VERSION ""

NS_ :

BS_:

BU_: MASTER BMSLV DASH DAQ DRIVE CHARGER TCS IMU DEBUG SPID DRS GPS SOC MOTEC

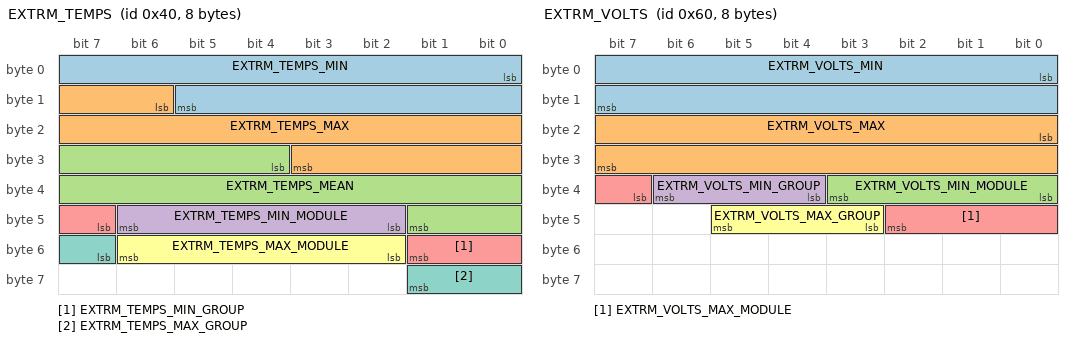
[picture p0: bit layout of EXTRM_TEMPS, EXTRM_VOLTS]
BO_ 64 EXTRM_TEMPS: 8 MASTER
 SG_ EXTRM_TEMPS_MIN : 0|14@1+ (0.0054931640625,0) [0|90] "�C" DEBUG
 SG_ EXTRM_TEMPS_MAX : 14|14@1+ (0.0054931640625,0) [0|90] "�C" DEBUG
 SG_ EXTRM_TEMPS_MEAN : 28|14@1+ (0.0054931640625,0) [0|90] "�C" DEBUG
 SG_ EXTRM_TEMPS_MIN_MODULE : 42|5@1+ (1,1) [1|32] "" DEBUG
 SG_ EXTRM_TEMPS_MIN_GROUP : 47|3@1+ (1,1) [1|6] "" DEBUG
 SG_ EXTRM_TEMPS_MAX_MODULE : 50|5@1+ (1,1) [1|32] "" DEBUG
 SG_ EXTRM_TEMPS_MAX_GROUP : 55|3@1+ (1,1) [1|6] "" DEBUG

BO_ 96 EXTRM_VOLTS: 8 MASTER
 SG_ EXTRM_VOLTS_MIN : 0|16@1+ (0.042724609375,1600) [1600|4400] "mV" DEBUG
 SG_ EXTRM_VOLTS_MAX : 16|16@1+ (0.042724609375,1600) [1600|4400] "mV" DEBUG
 SG_ EXTRM_VOLTS_MIN_MODULE : 32|4@1+ (1,1) [1|16] "" DEBUG
 SG_ EXTRM_VOLTS_MIN_GROUP : 36|3@1+ (1,1) [1|6] "" DEBUG
 SG_ EXTRM_VOLTS_MAX_MODULE : 39|4@1+ (1,1) [1|16] "" DEBUG
 SG_ EXTRM_VOLTS_MAX_GROUP : 43|3@1+ (1,1) [1|6] "" DEBUG

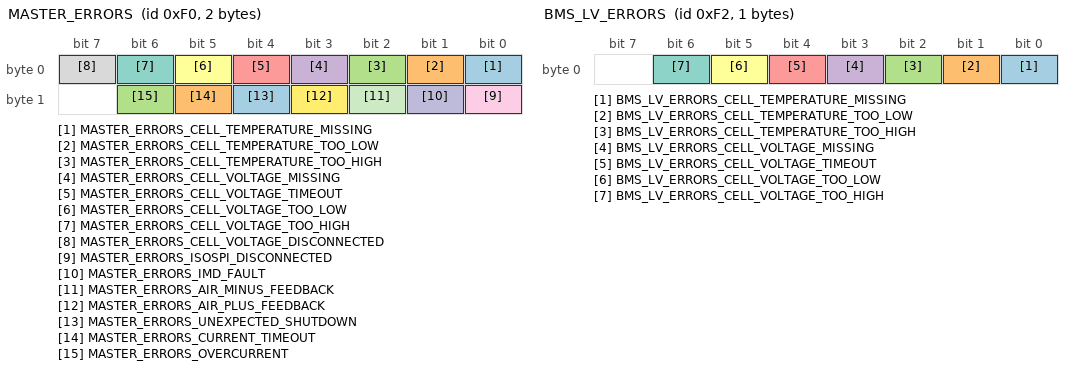
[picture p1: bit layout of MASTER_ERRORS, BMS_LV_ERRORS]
BO_ 240 MASTER_ERRORS: 2 MASTER
 SG_ MASTER_ERRORS_CELL_TEMPERATURE_MISSING : 0|1@1+ (1,0) [0|1] "" DEBUG
 SG_ MASTER_ERRORS_CELL_TEMPERATURE_TOO_LOW : 1|1@1+ (1,0) [0|1] "" DEBUG
 SG_ MASTER_ERRORS_CELL_TEMPERATURE_TOO_HIGH : 2|1@1+ (1,0) [0|1] "" DEBUG
 SG_ MASTER_ERRORS_CELL_VOLTAGE_MISSING : 3|1@1+ (1,0) [0|1] "" DEBUG
 SG_ MASTER_ERRORS_CELL_VOLTAGE_TIMEOUT : 4|1@1+ (1,0) [0|1] "" DEBUG
 SG_ MASTER_ERRORS_CELL_VOLTAGE_TOO_LOW : 5|1@1+ (1,0) [0|1] "" DEBUG
 SG_ MASTER_ERRORS_CELL_VOLTAGE_TOO_HIGH : 6|1@1+ (1,0) [0|1] "" DEBUG
 SG_ MASTER_ERRORS_CELL_VOLTAGE_DISCONNECTED : 7|1@1+ (1,0) [1|0] "" DEBUG
 SG_ MASTER_ERRORS_ISOSPI_DISCONNECTED : 8|1@1+ (1,0) [1|0] "" DEBUG
 SG_ MASTER_ERRORS_IMD_FAULT : 9|1@1+ (1,0) [0|1] "" DEBUG
 SG_ MASTER_ERRORS_AIR_MINUS_FEEDBACK : 10|1@1+ (1,0) [0|1] "" DEBUG
 SG_ MASTER_ERRORS_AIR_PLUS_FEEDBACK : 11|1@1+ (1,0) [0|1] "" DEBUG
 SG_ MASTER_ERRORS_UNEXPECTED_SHUTDOWN : 12|1@1+ (1,0) [0|1] "" DEBUG
 SG_ MASTER_ERRORS_CURRENT_TIMEOUT : 13|1@1+ (1,0) [0|1] "" DEBUG
 SG_ MASTER_ERRORS_OVERCURRENT : 14|1@1+ (1,0) [0|1] "" DEBUG

BO_ 242 BMS_LV_ERRORS: 1 BMSLV
 SG_ BMS_LV_ERRORS_CELL_TEMPERATURE_MISSING : 0|1@1+ (1,0) [0|1] "" DEBUG
 SG_ BMS_LV_ERRORS_CELL_TEMPERATURE_TOO_LOW : 1|1@1+ (1,0) [0|1] "" DEBUG
 SG_ BMS_LV_ERRORS_CELL_TEMPERATURE_TOO_HIGH : 2|1@1+ (1,0) [0|1] "" DEBUG
 SG_ BMS_LV_ERRORS_CELL_VOLTAGE_MISSING : 3|1@1+ (1,0) [0|1] "" DEBUG
 SG_ BMS_LV_ERRORS_CELL_VOLTAGE_TIMEOUT : 4|1@1+ (1,0) [0|1] "" DEBUG
 SG_ BMS_LV_ERRORS_CELL_VOLTAGE_TOO_LOW : 5|1@1+ (1,0) [0|1] "" DEBUG
 SG_ BMS_LV_ERRORS_CELL_VOLTAGE_TOO_HIGH : 6|1@1+ (1,0) [0|1] "" DEBUG

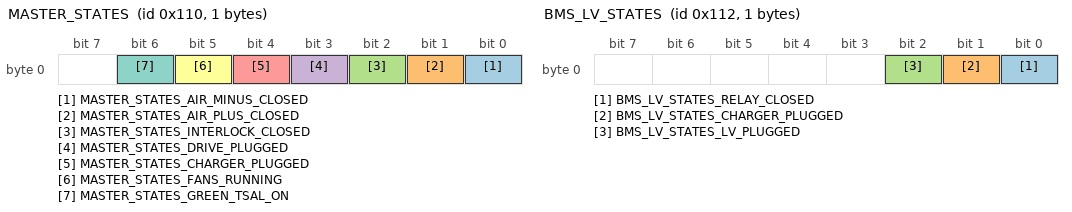
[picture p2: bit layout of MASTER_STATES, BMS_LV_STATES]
BO_ 272 MASTER_STATES: 1 MASTER
 SG_ MASTER_STATES_AIR_MINUS_CLOSED : 0|1@1+ (1,0) [0|1] "" DEBUG
 SG_ MASTER_STATES_AIR_PLUS_CLOSED : 1|1@1+ (1,0) [0|1] "" DEBUG
 SG_ MASTER_STATES_INTERLOCK_CLOSED : 2|1@1+ (1,0) [0|1] "" DEBUG
 SG_ MASTER_STATES_DRIVE_PLUGGED : 3|1@1+ (1,0) [0|1] "" DEBUG
 SG_ MASTER_STATES_CHARGER_PLUGGED : 4|1@1+ (1,0) [0|1] "" DEBUG
 SG_ MASTER_STATES_FANS_RUNNING : 5|1@1+ (1,0) [0|1] "" DEBUG
 SG_ MASTER_STATES_GREEN_TSAL_ON : 6|1@1+ (1,0) [0|1] "" DEBUG

BO_ 274 BMS_LV_STATES: 1 BMSLV
 SG_ BMS_LV_STATES_RELAY_CLOSED: 0|1@1+ (1,0) [0|1] "" DEBUG
 SG_ BMS_LV_STATES_CHARGER_PLUGGED: 1|1@1+ (1,0) [0|1] "" DEBUG
 SG_ BMS_LV_STATES_LV_PLUGGED: 2|1@1+ (1,0) [0|1] "" DEBUG

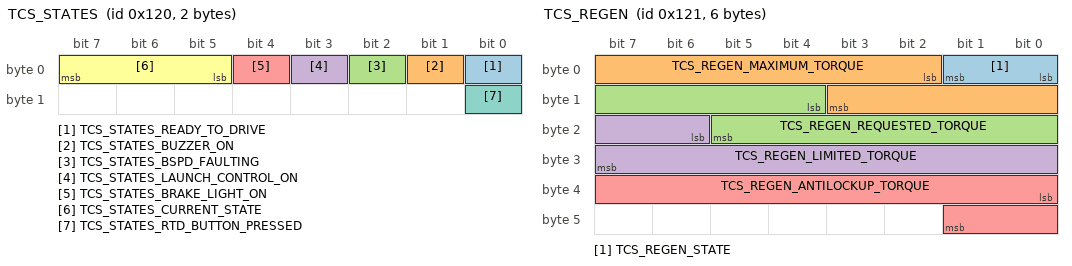
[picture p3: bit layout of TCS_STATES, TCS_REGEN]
BO_ 288 TCS_STATES: 2 TCS
 SG_ TCS_STATES_READY_TO_DRIVE : 0|1@1+ (1,0) [0|1] "" DEBUG
 SG_ TCS_STATES_BUZZER_ON : 1|1@1+ (1,0) [0|1] "" DEBUG
 SG_ TCS_STATES_BSPD_FAULTING : 2|1@1+ (1,0) [0|1] "" DEBUG
 SG_ TCS_STATES_LAUNCH_CONTROL_ON : 3|1@1+ (1,0) [0|1] "" DEBUG
 SG_ TCS_STATES_BRAKE_LIGHT_ON : 4|1@1+ (1,0) [0|1] "" DEBUG
 SG_ TCS_STATES_CURRENT_STATE : 5|3@1+ (1,0) [0|5] "" DEBUG
 SG_ TCS_STATES_RTD_BUTTON_PRESSED : 8|1@1+ (1,0) [0|1] "" DEBUG

 VAL_ 288 TCS_STATES_CURRENT_STATE 0 "SYSTEM_RESET" 1 "BATTERY_PACK_CHECK" 2 "DRIVE_CHECK" 3 "BRAKE_CHECK" 4 "READY_TO_DRIVE" 5 "BSPD_FAULT";

BO_ 289 TCS_REGEN: 6 TCS
 SG_ TCS_REGEN_STATE : 0|2@1+ (1,0) [0|3] "" DEBUG
 SG_ TCS_REGEN_MAXIMUM_TORQUE : 2|10@1+ (0.09765625,-100.0) [-100.0|0.0] "N.m" DEBUG
 SG_ TCS_REGEN_REQUESTED_TORQUE : 12|10@1+ (0.09765625,-100.0) [-100.0|0.0] "N.m" DEBUG
 SG_ TCS_REGEN_LIMITED_TORQUE : 22|10@1+ (0.09765625,-100.0) [-100.0|0.0] "N.m" DEBUG
 SG_ TCS_REGEN_ANTILOCKUP_TORQUE : 32|10@1+ (0.09765625,-100.0) [-100.0|0.0] "N.m" DEBUG

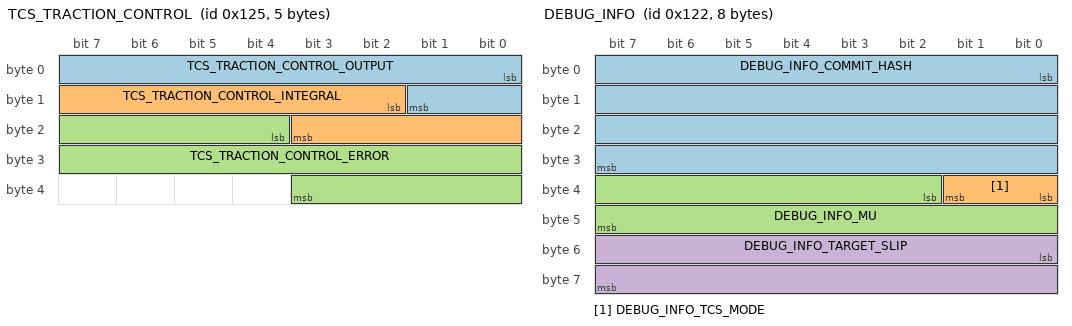
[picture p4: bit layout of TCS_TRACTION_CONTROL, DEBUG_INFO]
BO_ 293 TCS_TRACTION_CONTROL: 5 TCS
SG_ TCS_TRACTION_CONTROL_OUTPUT : 0|10@1- (1,0) [-1000|1000] "N.m" DEBUG
SG_ TCS_TRACTION_CONTROL_INTEGRAL : 10|10@1- (1,0) [-1000|1000] "" DEBUG
SG_ TCS_TRACTION_CONTROL_ERROR : 20|16@1- (0.001,0) [-10|10] "" DEBUG

BO_ 290 DEBUG_INFO: 8 TCS
 SG_ DEBUG_INFO_COMMIT_HASH : 0|32@1+ (1,0) [0|4294967295] "" DEBUG
 SG_ DEBUG_INFO_TCS_MODE : 32|2@1+ (1,0) [0|2] "" DEBUG
 SG_ DEBUG_INFO_MU : 34|14@1+ (0.0001,0) [0|1.6384] "" DEBUG
 SG_ DEBUG_INFO_TARGET_SLIP : 48|16@1+ (0.00001,0) [0|1] "" DEBUG

BO_ 291 PADDLE_STATE: 1 TCS
 SG_ PADDLE_STATE_RIGHT : 1|1@1+ (1,0) [0|1] "" DEBUG

VAL_ 289 TCS_REGEN_STATE 0 "TCS_REGEN_STATE_NOT_ALLOWED" 1 "TCS_REGEN_STATE_UNAVAILABLE" 2 "TCS_REGEN_STATE_AVAILABLE" 3 "TCS_REGEN_STATE_ACTIVATED";

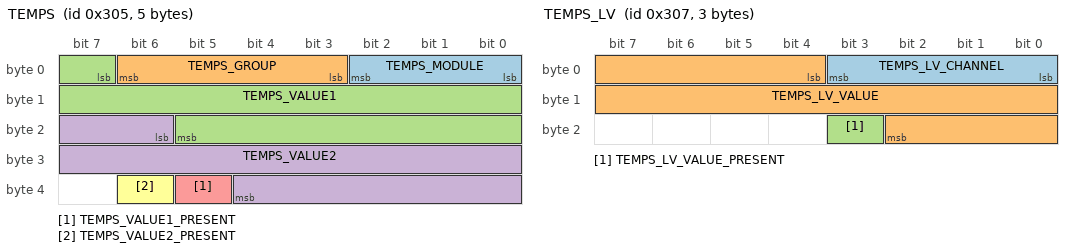
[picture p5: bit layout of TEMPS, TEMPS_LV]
BO_ 773 TEMPS: 5 MASTER
 SG_ TEMPS_MODULE : 0|3@1+ (1,0) [0|5] "" DEBUG
 SG_ TEMPS_GROUP : 3|4@1+ (1,0) [0|15] "" DEBUG
 SG_ TEMPS_VALUE1 : 7|15@1+ (0.00274658203125,0) [0|90] "⁰C" DEBUG
 SG_ TEMPS_VALUE2 : 22|15@1+ (0.00274658203125,0) [0|90] "⁰C" DEBUG
 SG_ TEMPS_VALUE1_PRESENT : 37|1@1+ (1,0) [0|1] "" DEBUG
 SG_ TEMPS_VALUE2_PRESENT : 38|1@1+ (1,0) [0|1] "" DEBUG

VAL_ 773 TEMPS_MODULE 0 "TEMPS_MODULE_MODULE_1" 1 "TEMPS_MODULE_MODULE_2" 2 "TEMPS_MODULE_MODULE_3" 3 "TEMPS_MODULE_MODULE_4" 4 "TEMPS_MODULE_MODULE_5" 5 "TEMPS_MODULE_MODULE_6";
VAL_ 773 TEMPS_GROUP 0 "TEMPS_GROUP_TEMPS_1_17" 1 "TEMPS_GROUP_TEMPS_2_18" 2 "TEMPS_GROUP_TEMPS_3_19" 3 "TEMPS_GROUP_TEMPS_4_20" 4 "TEMPS_GROUP_TEMPS_5_21" 5 "TEMPS_GROUP_TEMPS_6_22" 6 "TEMPS_GROUP_TEMPS_7_23" 7 "TEMPS_GROUP_TEMPS_8_24" 8 "TEMPS_GROUP_TEMPS_9_25" 9 "TEMPS_GROUP_TEMPS_10_26" 10 "TEMPS_GROUP_TEMPS_11_27" 11 "TEMPS_GROUP_TEMPS_12_28" 12 "TEMPS_GROUP_TEMPS_13_29" 13 "TEMPS_GROUP_TEMPS_14_30" 14 "TEMPS_GROUP_TEMPS_15_31" 15 "TEMPS_GROUP_TEMPS_16_32";

BO_ 775 TEMPS_LV: 3 BMSLV
 SG_ TEMPS_LV_CHANNEL : 0|4@1+ (1,0) [0|7] "" DEBUG
 SG_ TEMPS_LV_VALUE : 4|15@1+ (0.00274658203125,0) [0|90] "⁰C" DEBUG
 SG_ TEMPS_LV_VALUE_PRESENT : 19|1@1+ (1,0) [0|1] "" DEBUG

VAL_ 775 TEMPS_LV_CHANNEL 0 "TEMPS_LV_CHANNEL_TEMPS_1" 1 "TEMPS_LV_CHANNEL_TEMPS_2" 2 "TEMPS_LV_CHANNEL_TEMPS_3" 3 "TEMPS_LV_CHANNEL_TEMPS_4" 4 "TEMPS_LV_CHANNEL_TEMPS_5" 5 "TEMPS_LV_CHANNEL_TEMPS_6" 6 "TEMPS_LV_CHANNEL_TEMPS_7" 7 "TEMPS_LV_CHANNEL_TEMPS_8";

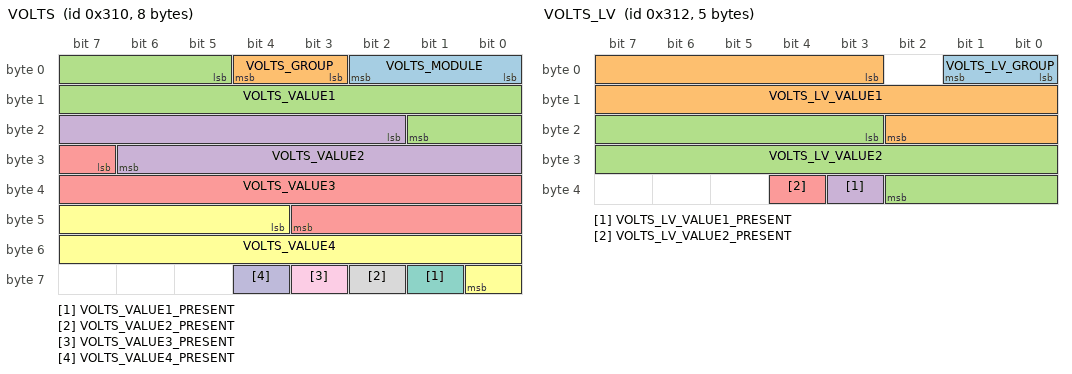
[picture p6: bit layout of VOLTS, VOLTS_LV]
BO_ 784 VOLTS: 8 MASTER
 SG_ VOLTS_MODULE : 0|3@1+ (1,0) [0|5] "" DEBUG
 SG_ VOLTS_GROUP : 3|2@1+ (1,0) [0|3] "" DEBUG
 SG_ VOLTS_VALUE1 : 5|13@1+ (0.30517578125,2000) [2000|4500] "mV" DEBUG
 SG_ VOLTS_VALUE2 : 18|13@1+ (0.30517578125,2000) [2000|4500] "mV" DEBUG
 SG_ VOLTS_VALUE3 : 31|13@1+ (0.30517578125,2000) [2000|4500] "mV" DEBUG
 SG_ VOLTS_VALUE4 : 44|13@1+ (0.30517578125,2000) [2000|4500] "mV" DEBUG
 SG_ VOLTS_VALUE1_PRESENT : 57|1@1+ (1,0) [0|1] "" DEBUG
 SG_ VOLTS_VALUE2_PRESENT : 58|1@1+ (1,0) [0|1] "" DEBUG
 SG_ VOLTS_VALUE3_PRESENT : 59|1@1+ (1,0) [0|1] "" DEBUG
 SG_ VOLTS_VALUE4_PRESENT : 60|1@1+ (1,0) [0|1] "" DEBUG

VAL_ 784 VOLTS_MODULE 0 "VOLTS_MODULE_MODULE_1" 1 "VOLTS_MODULE_MODULE_2" 2 "VOLTS_MODULE_MODULE_3" 3 "VOLTS_MODULE_MODULE_4" 4 "VOLTS_MODULE_MODULE_5" 5 "VOLTS_MODULE_MODULE_6";
VAL_ 784 VOLTS_GROUP 0 "VOLTS_GROUP_CELLS_1_2_3_4" 1 "VOLTS_GROUP_CELLS_5_6_7_8" 2 "VOLTS_GROUP_CELLS_9_10_11_12" 3 "VOLTS_GROUP_CELLS_13_14_15_16";

BO_ 786 VOLTS_LV: 5 BMSLV
 SG_ VOLTS_LV_GROUP : 0|2@1+ (1,0) [0|2] "" DEBUG
 SG_ VOLTS_LV_VALUE1 : 3|16@1+ (0.042724609375,1600) [1600|4400] "mV" DEBUG
 SG_ VOLTS_LV_VALUE2 : 19|16@1+ (0.042724609375,1600) [1600|4400] "mV" DEBUG
 SG_ VOLTS_LV_VALUE1_PRESENT : 35|1@1+ (1,0) [0|1] "" DEBUG
 SG_ VOLTS_LV_VALUE2_PRESENT : 36|1@1+ (1,0) [0|1] "" DEBUG

VAL_ 786 VOLTS_LV_GROUP 0 "VOLTS_LV_GROUP_CELLS_1_4" 1 "VOLTS_LV_GROUP_CELLS_2_5" 2 "VOLTS_LV_GROUP_CELLS_3_6";

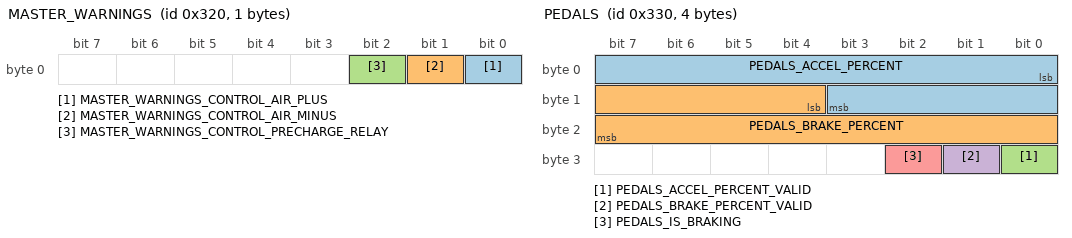
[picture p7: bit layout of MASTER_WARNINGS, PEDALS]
BO_ 800 MASTER_WARNINGS: 1 MASTER
 SG_ MASTER_WARNINGS_CONTROL_AIR_PLUS : 0|1@1+ (1,0) [0|1] "" DEBUG
 SG_ MASTER_WARNINGS_CONTROL_AIR_MINUS : 1|1@1+ (1,0) [0|1] "" DEBUG
 SG_ MASTER_WARNINGS_CONTROL_PRECHARGE_RELAY : 2|1@1+ (1,0) [0|1] "" DEBUG

BO_ 816 PEDALS: 4 TCS
 SG_ PEDALS_ACCEL_PERCENT : 0|12@1+ (0.02442002442002442,0) [0|100] "%" DEBUG
 SG_ PEDALS_BRAKE_PERCENT : 12|12@1+ (0.02442002442002442,0) [0|100] "%" DEBUG
 SG_ PEDALS_ACCEL_PERCENT_VALID : 24|1@1+ (1,0) [0|1] "" DEBUG
 SG_ PEDALS_BRAKE_PERCENT_VALID : 25|1@1+ (1,0) [0|1] "" DEBUG
 SG_ PEDALS_IS_BRAKING : 26|1@1+ (1,0) [0|1] "" DEBUG

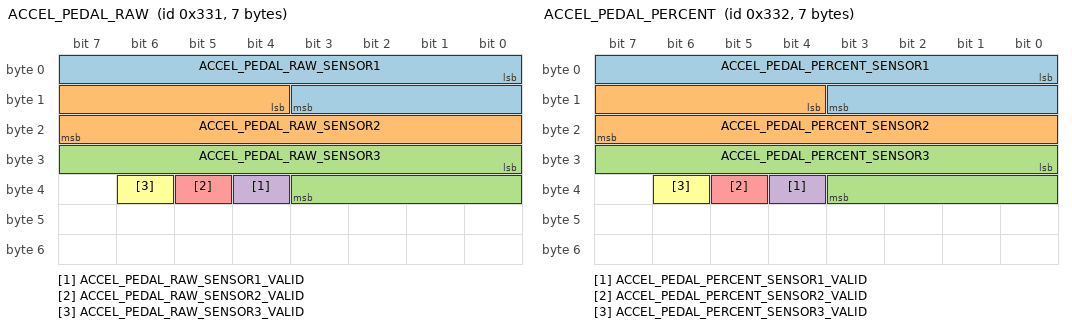
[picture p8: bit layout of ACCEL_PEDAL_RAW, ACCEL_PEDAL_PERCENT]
BO_ 817 ACCEL_PEDAL_RAW: 7 TCS
 SG_ ACCEL_PEDAL_RAW_SENSOR1 :  0|12@1+ (0.001343101343101343,0) [0|5.5] "V" DEBUG
 SG_ ACCEL_PEDAL_RAW_SENSOR2 : 12|12@1+ (0.001343101343101343,0) [0|5.5] "V" DEBUG
 SG_ ACCEL_PEDAL_RAW_SENSOR3 : 24|12@1+ (0.001343101343101343,0) [0|5.5] "V" DEBUG
 SG_ ACCEL_PEDAL_RAW_SENSOR1_VALID : 36|1@1+ (1,0) [0|1] "" DEBUG
 SG_ ACCEL_PEDAL_RAW_SENSOR2_VALID : 37|1@1+ (1,0) [0|1] "" DEBUG
 SG_ ACCEL_PEDAL_RAW_SENSOR3_VALID : 38|1@1+ (1,0) [0|1] "" DEBUG

BO_ 818 ACCEL_PEDAL_PERCENT: 7 TCS
 SG_ ACCEL_PEDAL_PERCENT_SENSOR1 :  0|12@1+ (0.02442002442002442,0) [0|100] "%" DEBUG
 SG_ ACCEL_PEDAL_PERCENT_SENSOR2 : 12|12@1+ (0.02442002442002442,0) [0|100] "%" DEBUG
 SG_ ACCEL_PEDAL_PERCENT_SENSOR3 : 24|12@1+ (0.02442002442002442,0) [0|100] "%" DEBUG
 SG_ ACCEL_PEDAL_PERCENT_SENSOR1_VALID : 36|1@1+ (1,0) [0|1] "" DEBUG
 SG_ ACCEL_PEDAL_PERCENT_SENSOR2_VALID : 37|1@1+ (1,0) [0|1] "" DEBUG
 SG_ ACCEL_PEDAL_PERCENT_SENSOR3_VALID : 38|1@1+ (1,0) [0|1] "" DEBUG

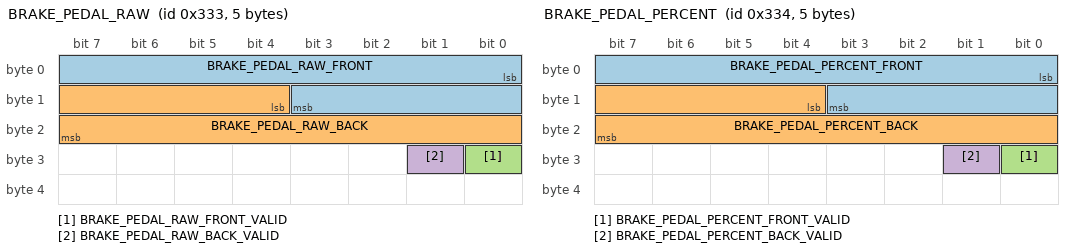
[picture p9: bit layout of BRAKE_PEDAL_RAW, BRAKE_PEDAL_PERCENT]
BO_ 819 BRAKE_PEDAL_RAW: 5 TCS
 SG_ BRAKE_PEDAL_RAW_FRONT : 0|12@1+ (0.001343101343101343,0) [0|5.5] "V" DEBUG
 SG_ BRAKE_PEDAL_RAW_BACK   : 12|12@1+ (0.001343101343101343,0) [0|5.5] "V" DEBUG
 SG_ BRAKE_PEDAL_RAW_FRONT_VALID : 24|1@1+ (1,0) [0|1] "" DEBUG
 SG_ BRAKE_PEDAL_RAW_BACK_VALID   : 25|1@1+ (1,0) [0|1] "" DEBUG

BO_ 820 BRAKE_PEDAL_PERCENT: 5 TCS
 SG_ BRAKE_PEDAL_PERCENT_FRONT :  0|12@1+ (0.02442002442002442,0) [0|100] "%" DEBUG
 SG_ BRAKE_PEDAL_PERCENT_BACK   : 12|12@1+ (0.02442002442002442,0) [0|100] "%" DEBUG
 SG_ BRAKE_PEDAL_PERCENT_FRONT_VALID : 24|1@1+ (1,0) [0|1] "" DEBUG
 SG_ BRAKE_PEDAL_PERCENT_BACK_VALID   : 25|1@1+ (1,0) [0|1] "" DEBUG

BO_ 500 ENERGY_STRATEGY_MODE: 1 TCS
 SG_ ENERGY_STRATEGY_MODE_ACTIVE : 0|2@1+ (1,0) [0|2] "" DEBUG

BO_ 825 CALCULATED_EFFICIENCIES: 2 TCS
 SG_ CALCULATED_EFFICIENCIES_DRIVE_EFFICIENCY : 0|8@1+ (0.390625,0) [0|100] "%" DEBUG
 SG_ CALCULATED_EFFICIENCIES_MOTOR_EFFICIENCY : 8|8@1+ (0.390625,0) [0|100] "%" DEBUG

BO_ 830 TCS_CONFIGURATION: 1 TCS
 SG_ TCS_CONFIGURATION_MAXIMUM_REGEN_TORQUE : 0|8@1+ (1.0,-100.0) [-100.0|0.0] "N.m" DEBUG

BO_ 831 TCS_TIMESTAMP: 3 TCS
 SG_ TCS_TIMESTAMP_CURRENT_TIMESTAMP : 0|24@1+ (1,0) [0|16777215] "ms" DEBUG

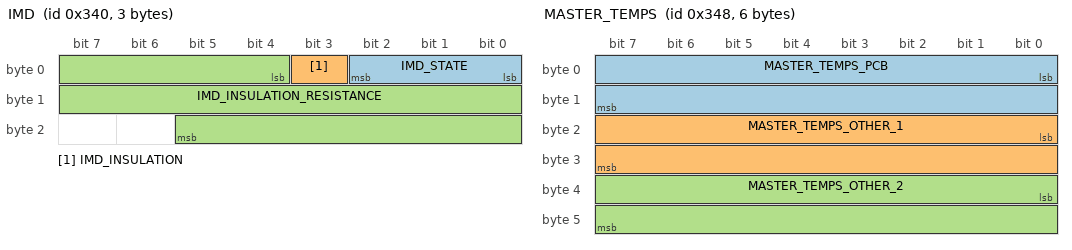
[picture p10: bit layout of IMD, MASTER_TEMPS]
BO_ 832 IMD: 3 MASTER
 SG_ IMD_STATE : 0|3@1+ (1,0) [0|5] "" DEBUG
 SG_ IMD_INSULATION : 3|1@1+ (1,0) [0|1] "" DEBUG
 SG_ IMD_INSULATION_RESISTANCE : 4|18@1+ (1,0) [0|80000] "kohm" DEBUG

VAL_ 832 IMD_STATE 0 "IMD_STATE_SHORT_CIRCUIT" 1 "IMD_STATE_NORMAL_CONDITION" 2 "IMD_STATE_UNDERVOLTAGE_CONDITION" 3 "IMD_STATE_SPEED_START_MEASUREMENT" 4 "IMD_STATE_DEVICE_ERROR" 5 "IMD_STATE_CONNECTION_FAULT_EARTH";
VAL_ 832 IMD_INSULATION 0 "IMD_INSULATION_GOOD" 1 "IMD_INSULATION_BAD";

BO_ 840 MASTER_TEMPS: 6 MASTER
 SG_ MASTER_TEMPS_PCB : 0|16@1+ (0.001373311970702678,0) [0|90] "⁰C" DEBUG
 SG_ MASTER_TEMPS_OTHER_1 : 16|16@1+ (0.001373311970702678,0) [0|90] "⁰C" DEBUG
 SG_ MASTER_TEMPS_OTHER_2 : 32|16@1+ (0.001373311970702678,0) [0|90] "⁰C" DEBUG

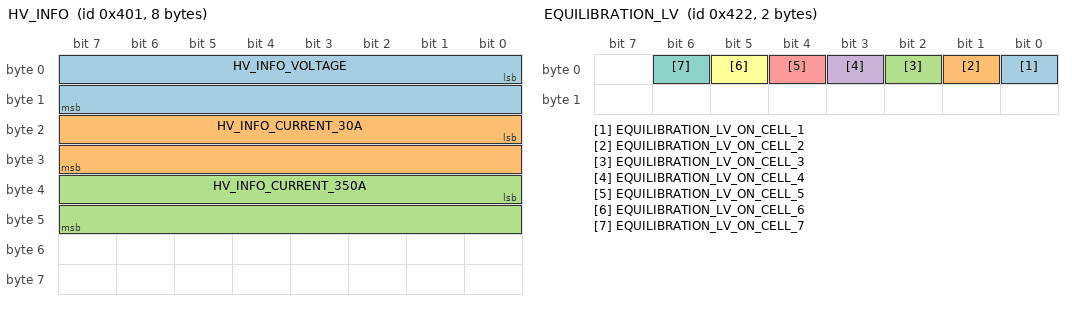
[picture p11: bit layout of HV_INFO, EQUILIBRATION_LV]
BO_ 1025 HV_INFO: 8 MASTER
 SG_ HV_INFO_VOLTAGE : 0|16@1+ (0.008392333984375,0) [0|550] "V" DEBUG
 SG_ HV_INFO_CURRENT_30A : 16|16@1+ (0.001220703125,-40) [-40|40] "A" DEBUG
 SG_ HV_INFO_CURRENT_350A : 32|16@1+ (0.01220703125,-400) [-400|400] "A" DEBUG

BO_ 1040 LV_INFO: 8 MASTER
 SG_ LV_INFO_VOLTAGE_28V : 0|16@1+ (0.000457763671875,0) [0|30] "V" DEBUG
 SG_ LV_INFO_VOLTAGE_24V : 16|16@1+ (0.0004119873046875,0) [0|27] "V" DEBUG

BO_ 1041 BMS_LV_INFO: 4 BMSLV
 SG_ BMS_LV_INFO_VOLTAGE : 0|16@1+ (0.000457763671875,0) [0|30] "V" DEBUG
 SG_ BMS_LV_INFO_ESTIMATED_SOC : 16|8@1+ (0.398,0) [0|100] "%" DEBUG

BO_ 1056 EQUILIBRATION: 3 MASTER
 SG_ EQUILIBRATION_MODULE : 0|3@1+ (1,0) [0|5] "" DEBUG
 SG_ EQUILIBRATION_ON_CELL_1 : 3|1@1+ (1,0) [0|1] "" DEBUG
 SG_ EQUILIBRATION_ON_CELL_2 : 4|1@1+ (1,0) [0|1] "" DEBUG
 SG_ EQUILIBRATION_ON_CELL_3 : 5|1@1+ (1,0) [0|1] "" DEBUG
 SG_ EQUILIBRATION_ON_CELL_4 : 6|1@1+ (1,0) [0|1] "" DEBUG
 SG_ EQUILIBRATION_ON_CELL_5 : 7|1@1+ (1,0) [0|1] "" DEBUG
 SG_ EQUILIBRATION_ON_CELL_6 : 8|1@1+ (1,0) [0|1] "" DEBUG
 SG_ EQUILIBRATION_ON_CELL_7 : 9|1@1+ (1,0) [0|1] "" DEBUG
 SG_ EQUILIBRATION_ON_CELL_8 : 10|1@1+ (1,0) [0|1] "" DEBUG
 SG_ EQUILIBRATION_ON_CELL_9 : 11|1@1+ (1,0) [0|1] "" DEBUG
 SG_ EQUILIBRATION_ON_CELL_10 : 12|1@1+ (1,0) [0|1] "" DEBUG
 SG_ EQUILIBRATION_ON_CELL_11 : 13|1@1+ (1,0) [0|1] "" DEBUG
 SG_ EQUILIBRATION_ON_CELL_12 : 14|1@1+ (1,0) [0|1] "" DEBUG
 SG_ EQUILIBRATION_ON_CELL_13 : 15|1@1+ (1,0) [0|1] "" DEBUG
 SG_ EQUILIBRATION_ON_CELL_14 : 16|1@1+ (1,0) [0|1] "" DEBUG
 SG_ EQUILIBRATION_ON_CELL_15 : 17|1@1+ (1,0) [0|1] "" DEBUG
 SG_ EQUILIBRATION_ON_CELL_16 : 18|1@1+ (1,0) [0|1] "" DEBUG

VAL_ 1056 EQUILIBRATION_MODULE 0 "EQUILIBRATION_MODULE_MODULE_1" 1 "EQUILIBRATION_MODULE_MODULE_2" 2 "EQUILIBRATION_MODULE_MODULE_3" 3 "EQUILIBRATION_MODULE_MODULE_4" 4 "EQUILIBRATION_MODULE_MODULE_5" 5 "EQUILIBRATION_MODULE_MODULE_6";

BO_ 1058 EQUILIBRATION_LV: 2 BMSLV
 SG_ EQUILIBRATION_LV_ON_CELL_1 : 0|1@1+ (1,0) [0|1] "" DEBUG
 SG_ EQUILIBRATION_LV_ON_CELL_2 : 1|1@1+ (1,0) [0|1] "" DEBUG
 SG_ EQUILIBRATION_LV_ON_CELL_3 : 2|1@1+ (1,0) [0|1] "" DEBUG
 SG_ EQUILIBRATION_LV_ON_CELL_4 : 3|1@1+ (1,0) [0|1] "" DEBUG
 SG_ EQUILIBRATION_LV_ON_CELL_5 : 4|1@1+ (1,0) [0|1] "" DEBUG
 SG_ EQUILIBRATION_LV_ON_CELL_6 : 5|1@1+ (1,0) [0|1] "" DEBUG
 SG_ EQUILIBRATION_LV_ON_CELL_7 : 6|1@1+ (1,0) [0|1] "" DEBUG

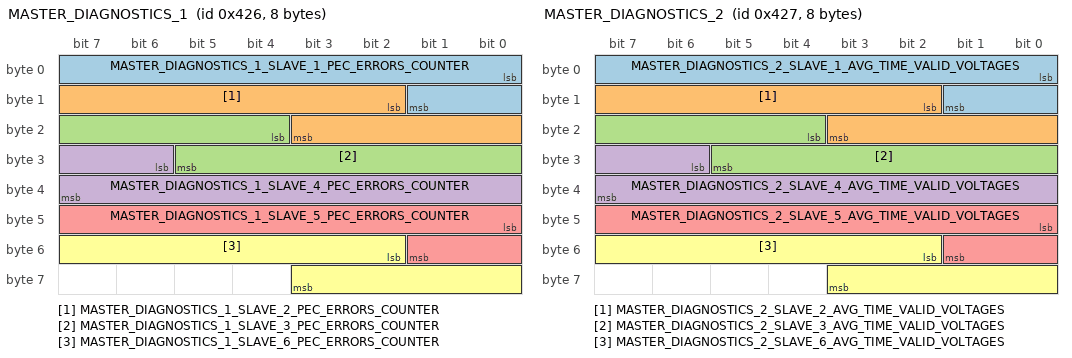
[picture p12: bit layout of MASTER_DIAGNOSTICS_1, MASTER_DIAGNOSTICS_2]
BO_ 1062 MASTER_DIAGNOSTICS_1: 8 MASTER
 SG_ MASTER_DIAGNOSTICS_1_SLAVE_1_PEC_ERRORS_COUNTER : 0|10@1+ (1,0) [0|1023] "" DEBUG
 SG_ MASTER_DIAGNOSTICS_1_SLAVE_2_PEC_ERRORS_COUNTER : 10|10@1+ (1,0) [0|1023] "" DEBUG
 SG_ MASTER_DIAGNOSTICS_1_SLAVE_3_PEC_ERRORS_COUNTER : 20|10@1+ (1,0) [0|1023] "" DEBUG
 SG_ MASTER_DIAGNOSTICS_1_SLAVE_4_PEC_ERRORS_COUNTER : 30|10@1+ (1,0) [0|1023] "" DEBUG
 SG_ MASTER_DIAGNOSTICS_1_SLAVE_5_PEC_ERRORS_COUNTER : 40|10@1+ (1,0) [0|1023] "" DEBUG
 SG_ MASTER_DIAGNOSTICS_1_SLAVE_6_PEC_ERRORS_COUNTER : 50|10@1+ (1,0) [0|1023] "" DEBUG

BO_ 1063 MASTER_DIAGNOSTICS_2: 8 MASTER
 SG_ MASTER_DIAGNOSTICS_2_SLAVE_1_AVG_TIME_VALID_VOLTAGES : 0|10@1+ (1,0) [0|1023] "ms" DEBUG
 SG_ MASTER_DIAGNOSTICS_2_SLAVE_2_AVG_TIME_VALID_VOLTAGES : 10|10@1+ (1,0) [0|1023] "ms" DEBUG
 SG_ MASTER_DIAGNOSTICS_2_SLAVE_3_AVG_TIME_VALID_VOLTAGES : 20|10@1+ (1,0) [0|1023] "ms" DEBUG
 SG_ MASTER_DIAGNOSTICS_2_SLAVE_4_AVG_TIME_VALID_VOLTAGES : 30|10@1+ (1,0) [0|1023] "ms" DEBUG
 SG_ MASTER_DIAGNOSTICS_2_SLAVE_5_AVG_TIME_VALID_VOLTAGES : 40|10@1+ (1,0) [0|1023] "ms" DEBUG
 SG_ MASTER_DIAGNOSTICS_2_SLAVE_6_AVG_TIME_VALID_VOLTAGES : 50|10@1+ (1,0) [0|1023] "ms" DEBUG

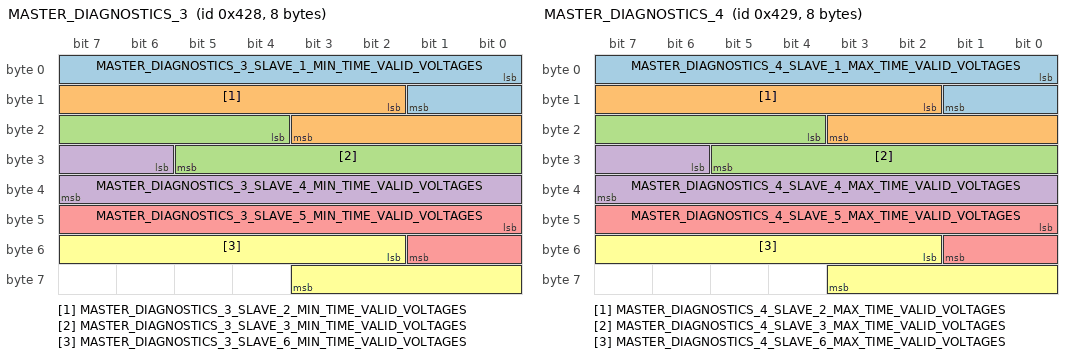
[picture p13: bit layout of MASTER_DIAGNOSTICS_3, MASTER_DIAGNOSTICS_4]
BO_ 1064 MASTER_DIAGNOSTICS_3: 8 MASTER
 SG_ MASTER_DIAGNOSTICS_3_SLAVE_1_MIN_TIME_VALID_VOLTAGES : 0|10@1+ (1,0) [0|1023] "ms" DEBUG
 SG_ MASTER_DIAGNOSTICS_3_SLAVE_2_MIN_TIME_VALID_VOLTAGES : 10|10@1+ (1,0) [0|1023] "ms" DEBUG
 SG_ MASTER_DIAGNOSTICS_3_SLAVE_3_MIN_TIME_VALID_VOLTAGES : 20|10@1+ (1,0) [0|1023] "ms" DEBUG
 SG_ MASTER_DIAGNOSTICS_3_SLAVE_4_MIN_TIME_VALID_VOLTAGES : 30|10@1+ (1,0) [0|1023] "ms" DEBUG
 SG_ MASTER_DIAGNOSTICS_3_SLAVE_5_MIN_TIME_VALID_VOLTAGES : 40|10@1+ (1,0) [0|1023] "ms" DEBUG
 SG_ MASTER_DIAGNOSTICS_3_SLAVE_6_MIN_TIME_VALID_VOLTAGES : 50|10@1+ (1,0) [0|1023] "ms" DEBUG

BO_ 1065 MASTER_DIAGNOSTICS_4: 8 MASTER
 SG_ MASTER_DIAGNOSTICS_4_SLAVE_1_MAX_TIME_VALID_VOLTAGES : 0|10@1+ (1,0) [0|1023] "ms" DEBUG
 SG_ MASTER_DIAGNOSTICS_4_SLAVE_2_MAX_TIME_VALID_VOLTAGES : 10|10@1+ (1,0) [0|1023] "ms" DEBUG
 SG_ MASTER_DIAGNOSTICS_4_SLAVE_3_MAX_TIME_VALID_VOLTAGES : 20|10@1+ (1,0) [0|1023] "ms" DEBUG
 SG_ MASTER_DIAGNOSTICS_4_SLAVE_4_MAX_TIME_VALID_VOLTAGES : 30|10@1+ (1,0) [0|1023] "ms" DEBUG
 SG_ MASTER_DIAGNOSTICS_4_SLAVE_5_MAX_TIME_VALID_VOLTAGES : 40|10@1+ (1,0) [0|1023] "ms" DEBUG
 SG_ MASTER_DIAGNOSTICS_4_SLAVE_6_MAX_TIME_VALID_VOLTAGES : 50|10@1+ (1,0) [0|1023] "ms" DEBUG

BO_ 1072 FORCE_FANS: 1 MASTER
 SG_ FORCE_FANS_ENABLED : 0|1@1+ (1,0) [0|1] "" MASTER
 SG_ FORCE_FANS_DUTY_CYCLE: 1|7@1+ (1,0) [0|100] "" MASTER

BO_ 1050 TCS_SETTINGS_READ: 2 TCS
 SG_ TCS_SETTINGS_READ_WORD_INDEX : 0|16@1+ (1,0) [0|65535] "" TCS

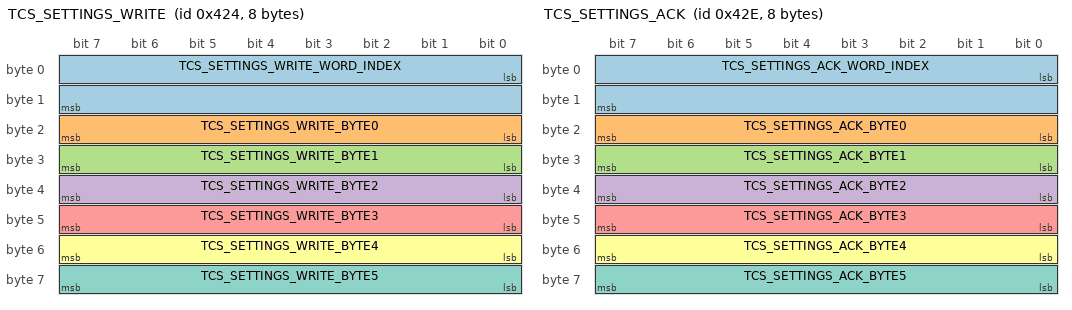
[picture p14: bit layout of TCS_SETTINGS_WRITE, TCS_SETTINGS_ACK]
BO_ 1060 TCS_SETTINGS_WRITE: 8 TCS
 SG_ TCS_SETTINGS_WRITE_WORD_INDEX : 0|16@1+ (1,0) [0|65535] "" TCS
 SG_ TCS_SETTINGS_WRITE_BYTE0 : 16|8@1+ (1,0) [0|255] "" TCS
 SG_ TCS_SETTINGS_WRITE_BYTE1 : 24|8@1+ (1,0) [0|255] "" TCS
 SG_ TCS_SETTINGS_WRITE_BYTE2 : 32|8@1+ (1,0) [0|255] "" TCS
 SG_ TCS_SETTINGS_WRITE_BYTE3 : 40|8@1+ (1,0) [0|255] "" TCS
 SG_ TCS_SETTINGS_WRITE_BYTE4 : 48|8@1+ (1,0) [0|255] "" TCS
 SG_ TCS_SETTINGS_WRITE_BYTE5 : 56|8@1+ (1,0) [0|255] "" TCS

BO_ 1070 TCS_SETTINGS_ACK: 8 TCS
 SG_ TCS_SETTINGS_ACK_WORD_INDEX : 0|16@1+ (1,0) [0|65535] "" TCS
 SG_ TCS_SETTINGS_ACK_BYTE0 : 16|8@1+ (1,0) [0|255] "" TCS
 SG_ TCS_SETTINGS_ACK_BYTE1 : 24|8@1+ (1,0) [0|255] "" TCS
 SG_ TCS_SETTINGS_ACK_BYTE2 : 32|8@1+ (1,0) [0|255] "" TCS
 SG_ TCS_SETTINGS_ACK_BYTE3 : 40|8@1+ (1,0) [0|255] "" TCS
 SG_ TCS_SETTINGS_ACK_BYTE4 : 48|8@1+ (1,0) [0|255] "" TCS
 SG_ TCS_SETTINGS_ACK_BYTE5 : 56|8@1+ (1,0) [0|255] "" TCS

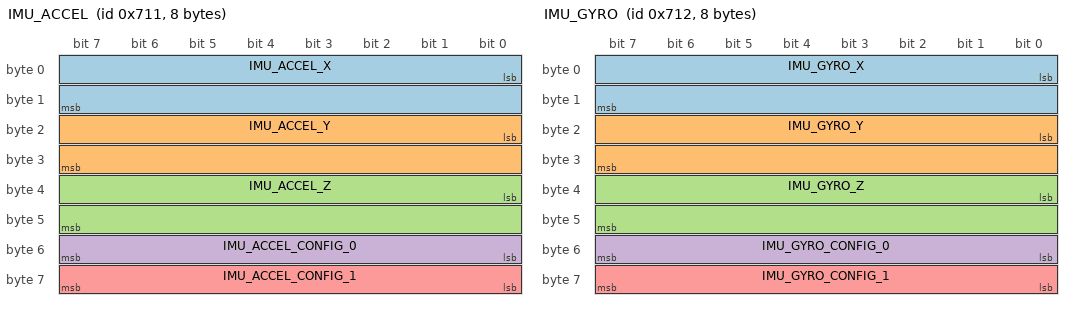
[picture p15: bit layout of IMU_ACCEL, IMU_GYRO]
BO_ 1809 IMU_ACCEL: 8 IMU
 SG_ IMU_ACCEL_X : 0|16@1- (0.00012207031,0) [-4|4] "g" DEBUG
 SG_ IMU_ACCEL_Y : 16|16@1- (0.00012207031,0) [-4|4] "g" DEBUG
 SG_ IMU_ACCEL_Z : 32|16@1- (0.00012207031,0) [-4|4] "g" DEBUG
 SG_ IMU_ACCEL_CONFIG_0 : 48|8@1+ (1,0) [0|255] "" DEBUG
 SG_ IMU_ACCEL_CONFIG_1 : 56|8@1+ (1,0) [0|255] "" DEBUG

BO_ 1810 IMU_GYRO: 8 IMU
 SG_ IMU_GYRO_X : 0|16@1- (0.015259,0) [-500|500] "dps" DEBUG
 SG_ IMU_GYRO_Y : 16|16@1- (0.015259,0) [-500|500] "dps" DEBUG
 SG_ IMU_GYRO_Z : 32|16@1- (0.015259,0) [-500|500] "dps" DEBUG
 SG_ IMU_GYRO_CONFIG_0 : 48|8@1+ (1,0) [0|255] "" DEBUG
 SG_ IMU_GYRO_CONFIG_1 : 56|8@1+ (1,0) [0|255] "" DEBUG

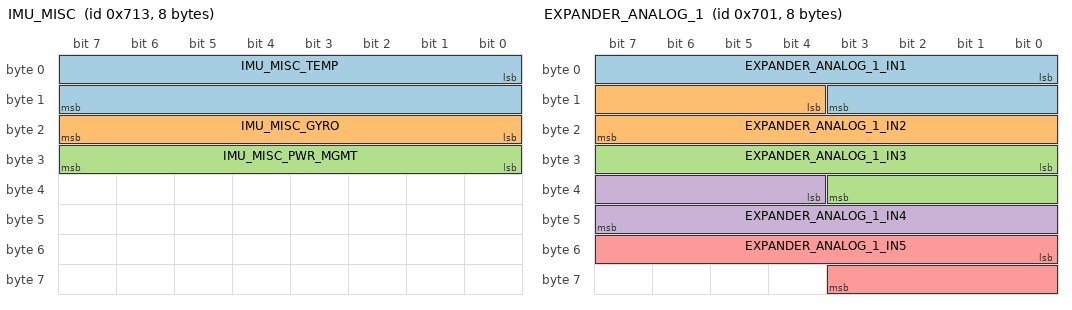
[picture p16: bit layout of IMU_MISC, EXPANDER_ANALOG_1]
BO_ 1811 IMU_MISC: 8 IMU
 SG_ IMU_MISC_TEMP : 0|16@1+ (1,0) [0|65535] "" DEBUG
 SG_ IMU_MISC_GYRO : 16|8@1+ (1,0) [0|255] "" DEBUG
 SG_ IMU_MISC_PWR_MGMT : 24|8@1+ (1,0) [0|255] "" DEBUG

BO_ 1793 EXPANDER_ANALOG_1: 8 EXPANDER
 SG_ EXPANDER_ANALOG_1_IN1 : 0|12@1+ (1,0) [0|4095] "" DEBUG
 SG_ EXPANDER_ANALOG_1_IN2 : 12|12@1+ (1,0) [0|4095] "" DEBUG
 SG_ EXPANDER_ANALOG_1_IN3 : 24|12@1+ (1,0) [0|4095] "" DEBUG
 SG_ EXPANDER_ANALOG_1_IN4 : 36|12@1+ (1,0) [0|4095] "" DEBUG
 SG_ EXPANDER_ANALOG_1_IN5 : 48|12@1+ (1,0) [0|4095] "" DEBUG

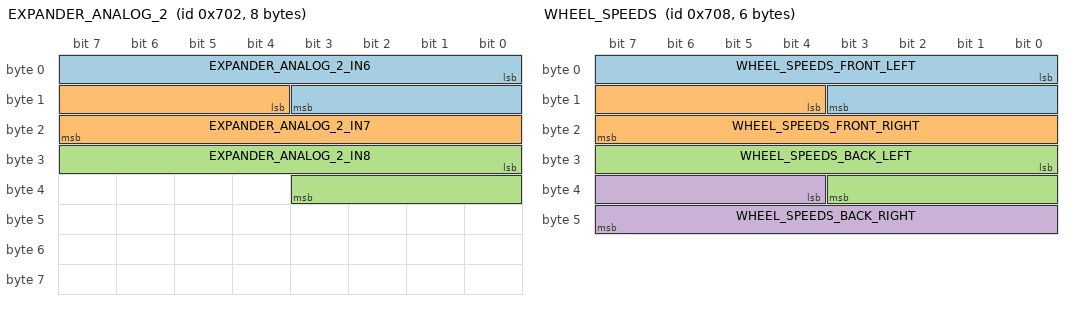
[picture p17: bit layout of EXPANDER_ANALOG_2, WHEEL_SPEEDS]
BO_ 1794 EXPANDER_ANALOG_2: 8 EXPANDER
 SG_ EXPANDER_ANALOG_2_IN6 : 0|12@1+ (1,0) [0|4095] "" DEBUG
 SG_ EXPANDER_ANALOG_2_IN7 : 12|12@1+ (1,0) [0|4095] "" DEBUG
 SG_ EXPANDER_ANALOG_2_IN8 : 24|12@1+ (1,0) [0|4095] "" DEBUG

BO_ 1800 WHEEL_SPEEDS: 6 TCS
  SG_ WHEEL_SPEEDS_FRONT_LEFT: 0|12@1+ (1,0) [0|4095] "RPM" DEBUG
  SG_ WHEEL_SPEEDS_FRONT_RIGHT: 12|12@1+ (1,0) [0|4095] "RPM" DEBUG
  SG_ WHEEL_SPEEDS_BACK_LEFT: 24|12@1+ (1,0) [0|4095] "RPM" DEBUG
  SG_ WHEEL_SPEEDS_BACK_RIGHT: 36|12@1+ (1,0) [0|4095] "RPM" DEBUG

BO_ 1850 KF_VELOCITY: 8 TCS
  SG_ KF_VELOCITY_OUTPUT: 0|32@1+ (0.01,0) [0|100] "m/s" KF

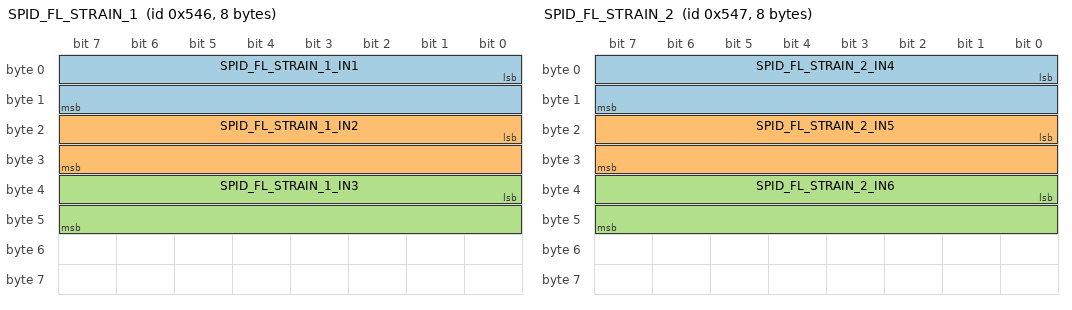
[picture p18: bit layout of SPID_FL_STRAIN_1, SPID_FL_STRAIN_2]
BO_ 1350 SPID_FL_STRAIN_1: 8 SPID
 SG_ SPID_FL_STRAIN_1_IN1 : 0|16@1+ (0.01068115234375,-360.0) [-360|340] "MPa" DEBUG
 SG_ SPID_FL_STRAIN_1_IN2 : 16|16@1+ (0.01068115234375,-360.0) [-360|340] "MPa" DEBUG
 SG_ SPID_FL_STRAIN_1_IN3 : 32|16@1+ (0.01068115234375,-360.0) [-360|340] "MPa" DEBUG

BO_ 1351 SPID_FL_STRAIN_2: 8 SPID
 SG_ SPID_FL_STRAIN_2_IN4 : 0|16@1+ (0.01068115234375,-360.0) [-360|340] "MPa" DEBUG
 SG_ SPID_FL_STRAIN_2_IN5 : 16|16@1+ (0.01068115234375,-360.0) [-360|340] "MPa" DEBUG
 SG_ SPID_FL_STRAIN_2_IN6 : 32|16@1+ (0.01068115234375,-360.0) [-360|340] "MPa" DEBUG

BO_ 1352 SPID_FR_STRAIN_1: 8 SPID
 SG_ SPID_FR_STRAIN_1_IN1 : 0|16@1+ (0.01068115234375,-360.0) [-360|340] "MPa" DEBUG
 SG_ SPID_FR_STRAIN_1_IN2 : 16|16@1+ (0.01068115234375,-360.0) [-360|340] "MPa" DEBUG
 SG_ SPID_FR_STRAIN_1_IN3 : 32|16@1+ (0.01068115234375,-360.0) [-360|340] "MPa" DEBUG

BO_ 1353 SPID_FR_STRAIN_2: 8 SPID
 SG_ SPID_FR_STRAIN_2_IN4 : 0|16@1+ (0.01068115234375,-360.0) [-360|340] "MPa" DEBUG
 SG_ SPID_FR_STRAIN_2_IN5 : 16|16@1+ (0.01068115234375,-360.0) [-360|340] "MPa" DEBUG
 SG_ SPID_FR_STRAIN_2_IN6 : 32|16@1+ (0.01068115234375,-360.0) [-360|340] "MPa" DEBUG

BO_ 1354 SPID_RL_STRAIN_1: 8 SPID
 SG_ SPID_RL_STRAIN_1_IN1 : 0|16@1+ (0.01068115234375,-360.0) [-360|340] "MPa" DEBUG
 SG_ SPID_RL_STRAIN_1_IN2 : 16|16@1+ (0.01068115234375,-360.0) [-360|340] "MPa" DEBUG
 SG_ SPID_RL_STRAIN_1_IN3 : 32|16@1+ (0.01068115234375,-360.0) [-360|340] "MPa" DEBUG

BO_ 1355 SPID_RL_STRAIN_2: 8 SPID
 SG_ SPID_RL_STRAIN_2_IN4 : 0|16@1+ (0.01068115234375,-360.0) [-360|340] "MPa" DEBUG
 SG_ SPID_RL_STRAIN_2_IN5 : 16|16@1+ (0.01068115234375,-360.0) [-360|340] "MPa" DEBUG
 SG_ SPID_RL_STRAIN_2_IN6 : 32|16@1+ (0.01068115234375,-360.0) [-360|340] "MPa" DEBUG

BO_ 1356 SPID_RR_STRAIN_1: 8 SPID
 SG_ SPID_RR_STRAIN_1_IN1 : 0|16@1+ (0.01068115234375,-360.0) [-360|340] "MPa" DEBUG
 SG_ SPID_RR_STRAIN_1_IN2 : 16|16@1+ (0.01068115234375,-360.0) [-360|340] "MPa" DEBUG
 SG_ SPID_RR_STRAIN_1_IN3 : 32|16@1+ (0.01068115234375,-360.0) [-360|340] "MPa" DEBUG

BO_ 1357 SPID_RR_STRAIN_2: 8 SPID
 SG_ SPID_RR_STRAIN_2_IN4 : 0|16@1+ (0.01068115234375,-360.0) [-360|340] "MPa" DEBUG
 SG_ SPID_RR_STRAIN_2_IN5 : 16|16@1+ (0.01068115234375,-360.0) [-360|340] "MPa" DEBUG
 SG_ SPID_RR_STRAIN_2_IN6 : 32|16@1+ (0.01068115234375,-360.0) [-360|340] "MPa" DEBUG

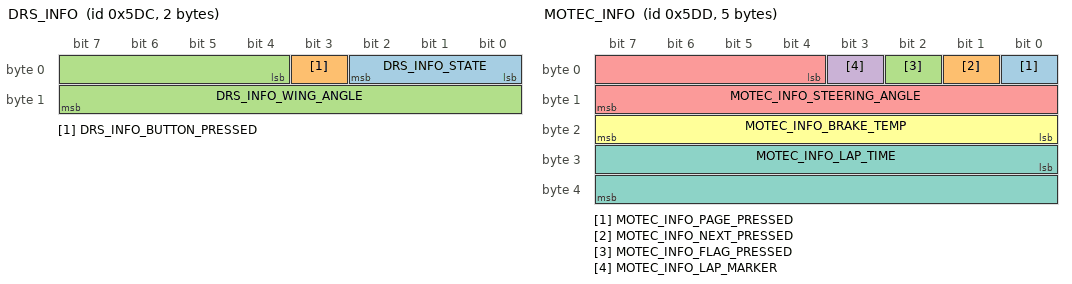
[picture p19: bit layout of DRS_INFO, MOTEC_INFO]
BO_ 1500 DRS_INFO: 2 DRS
 SG_ DRS_INFO_STATE : 0|3@1+ (1,0) [0|4] "" DEBUG
 SG_ DRS_INFO_BUTTON_PRESSED : 3|1@1+ (1,0) [0|1] "" DEBUG
 SG_ DRS_INFO_WING_ANGLE : 4|12@1+ (0.04394531,0) [0|180] "⁰" DEBUG

VAL_ 1500 DRS_INFO_STATE 0 "DRS_INFO_STATE_INIT" 1 "DRS_INFO_STATE_CLOSING" 2 "DRS_INFO_STATE_CLOSED" 3 "DRS_INFO_STATE_OPENING" 4 "DRS_INFO_STATE_OPENED";

BO_ 1600 GPS: 8 GPS
 SG_ GPS_LATITUDE : 0|32@1- (0.0000001,0) [-90|90] "deg" DEBUG
 SG_ GPS_LONGITUDE : 32|32@1- (0.0000001,0) [-180|180] "deg" DEBUG

BO_ 1610 LAP: 1 GPS
 SG_ LAP_ENDED : 0|1@1+ (1,0) [0|1] "" DEBUG

BO_ 1620 GPS_DISTANCE_DRIVEN: 2 GPS
 SG_ GPS_DISTANCE_DRIVEN_SOC : 0|16@1+ (1,0) [0|65535] "m" DEBUG

BO_ 1700 SOC: 1 SOC
 SG_ SOC_DIFFERENTIAL_LAPS : 0|8@1- (1,0) [-128|127] "lap(s)" DEBUG

BO_ 1701 SOC_SET_COORDS: 1 SOC
 SG_ SOC_SET_COORDS_START : 0|1@1+ (1,0) [0|1] "" DEBUG

BO_ 1501 MOTEC_INFO: 5 MOTEC
 SG_ MOTEC_INFO_PAGE_PRESSED   : 0|1@1+ (1,0) [0|1] "" DEBUG
 SG_ MOTEC_INFO_NEXT_PRESSED   : 1|1@1+ (1,0) [0|1] "" DEBUG
 SG_ MOTEC_INFO_FLAG_PRESSED   : 2|1@1+ (1,0) [0|1] "" DEBUG
 SG_ MOTEC_INFO_LAP_MARKER     : 3|1@1+ (1,0) [0|1] "" DEBUG
 SG_ MOTEC_INFO_STEERING_ANGLE : 4|12@1- (0.0732421875,0) [-130|130] "⁰" DEBUG
 SG_ MOTEC_INFO_BRAKE_TEMP     : 16|8@1+ (3.90625, 0) [0|1000] "°" DEBUG
 SG_ MOTEC_INFO_LAP_TIME       : 24|16@1+ (0.00274658203, 0) [0|180] "s" DEBUG

CM_ BU_ MASTER "FPM Master";
CM_ BU_ TCS "FPM Traction Control System";
CM_ BU_ BMSLV "FPM LV battery";
CM_ BU_ DRIVE "Unitek BAMOCAR D3";
CM_ BU_ CHARGER "Brusa NLG5";
CM_ BU_ DRS "FPM Drag Reduction System";

BA_DEF_  "Bus Speed" STRING ;
BA_DEF_  "BusType" STRING ;
BA_DEF_ BO_  "GenMsgSendType" ENUM  "Cyclic","not_used","not_used","not_used","not_used","Cyclic","not_used","IfActive","NoMsgSendType";
BA_DEF_ SG_  "GenSigSendType" ENUM  "Cyclic","OnWrite","OnWriteWithRepetition","OnChange","OnChangeWithRepetition","IfActive","IfActiveWithRepetition","NoSigSendType";
BA_DEF_DEF_  "Bus Speed" "500k";
BA_DEF_DEF_  "BusType" "CAN";
BA_DEF_DEF_  "GenMsgSendType" "NoMsgSendType";
BA_DEF_DEF_  "GenSigSendType" "Cyclic";
